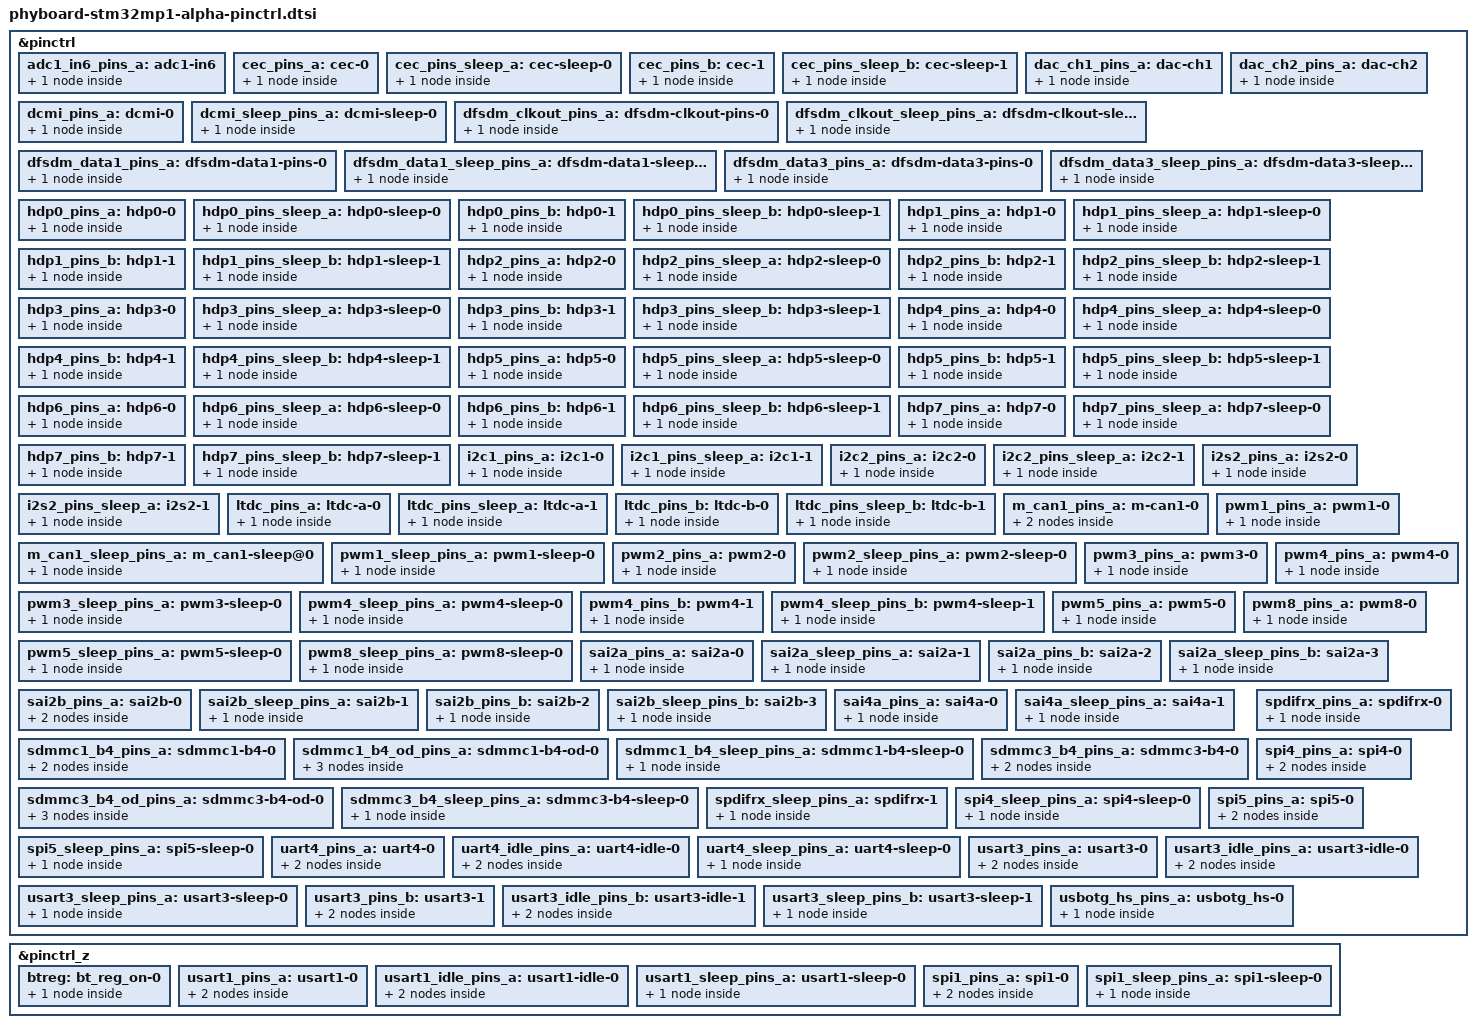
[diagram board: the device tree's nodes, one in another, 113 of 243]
// SPDX-License-Identifier: (GPL-2.0+ OR BSD-3-Clause)
/*
 * Copyright (C) PHYTEC GmbH 2019-2020 - All Rights Reserved
 * Author: Dom VOVARD <dom.vovard@linrt.com>.
 */

#include <dt-bindings/pinctrl/stm32-pinfunc.h>

&pinctrl {
			adc1_in6_pins_a: adc1-in6 {
				pins {
					pinmux = <STM32_PINMUX('F', 12, ANALOG)>;
				};
			};

			cec_pins_a: cec-0 {
				pins {
					pinmux = <STM32_PINMUX('A', 15, AF4)>;
					bias-disable;
					drive-open-drain;
					slew-rate = <0>;
				};
			};

			cec_pins_sleep_a: cec-sleep-0 {
				pins {
					pinmux = <STM32_PINMUX('A', 15, ANALOG)>; /* HDMI_CEC */
				};
			};

			cec_pins_b: cec-1 {
				pins {
					pinmux = <STM32_PINMUX('B', 6, AF5)>;
					bias-disable;
					drive-open-drain;
					slew-rate = <0>;
				};
			};

			cec_pins_sleep_b: cec-sleep-1 {
				pins {
					pinmux = <STM32_PINMUX('B', 6, ANALOG)>; /* HDMI_CEC */
				};
			};

			dac_ch1_pins_a: dac-ch1 {
				pins {
					pinmux = <STM32_PINMUX('A', 4, ANALOG)>;
				};
			};

			dac_ch2_pins_a: dac-ch2 {
				pins {
					pinmux = <STM32_PINMUX('A', 5, ANALOG)>;
				};
			};

			dcmi_pins_a: dcmi-0 {
				pins {
					pinmux = <STM32_PINMUX('H', 8,  AF13)>,/* DCMI_HSYNC */
						 <STM32_PINMUX('B', 7,  AF13)>,/* DCMI_VSYNC */
						 <STM32_PINMUX('A', 6,  AF13)>,/* DCMI_PIXCLK */
						 <STM32_PINMUX('H', 9,  AF13)>,/* DCMI_D0 */
						 <STM32_PINMUX('H', 10, AF13)>,/* DCMI_D1 */
						 <STM32_PINMUX('H', 11, AF13)>,/* DCMI_D2 */
						 <STM32_PINMUX('H', 12, AF13)>,/* DCMI_D3 */
						 <STM32_PINMUX('H', 14, AF13)>,/* DCMI_D4 */
						 <STM32_PINMUX('I', 4,  AF13)>,/* DCMI_D5 */
						 <STM32_PINMUX('B', 8,  AF13)>,/* DCMI_D6 */
						 <STM32_PINMUX('E', 6,  AF13)>,/* DCMI_D7 */
						 <STM32_PINMUX('I', 1,  AF13)>,/* DCMI_D8 */
						 <STM32_PINMUX('H', 7,  AF13)>,/* DCMI_D9 */
						 <STM32_PINMUX('I', 3,  AF13)>,/* DCMI_D10 */
						 <STM32_PINMUX('H', 15, AF13)>;/* DCMI_D11 */
					bias-disable;
				};
			};

			dcmi_sleep_pins_a: dcmi-sleep-0 {
				pins {
					pinmux = <STM32_PINMUX('H', 8,  ANALOG)>,/* DCMI_HSYNC */
						 <STM32_PINMUX('B', 7,  ANALOG)>,/* DCMI_VSYNC */
						 <STM32_PINMUX('A', 6,  ANALOG)>,/* DCMI_PIXCLK */
						 <STM32_PINMUX('H', 9,  ANALOG)>,/* DCMI_D0 */
						 <STM32_PINMUX('H', 10, ANALOG)>,/* DCMI_D1 */
						 <STM32_PINMUX('H', 11, ANALOG)>,/* DCMI_D2 */
						 <STM32_PINMUX('H', 12, ANALOG)>,/* DCMI_D3 */
						 <STM32_PINMUX('H', 14, ANALOG)>,/* DCMI_D4 */
						 <STM32_PINMUX('I', 4,  ANALOG)>,/* DCMI_D5 */
						 <STM32_PINMUX('B', 8,  ANALOG)>,/* DCMI_D6 */
						 <STM32_PINMUX('E', 6,  ANALOG)>,/* DCMI_D7 */
						 <STM32_PINMUX('I', 1,  ANALOG)>,/* DCMI_D8 */
						 <STM32_PINMUX('H', 7,  ANALOG)>,/* DCMI_D9 */
						 <STM32_PINMUX('I', 3,  ANALOG)>,/* DCMI_D10 */
						 <STM32_PINMUX('H', 15, ANALOG)>;/* DCMI_D11 */
				};
			};

			dfsdm_clkout_pins_a: dfsdm-clkout-pins-0 {
				pins {
					pinmux = <STM32_PINMUX('B', 13, AF3)>; /* DFSDM_CKOUT */
					bias-disable;
					drive-push-pull;
					slew-rate = <1>;
				};
			};

			dfsdm_clkout_sleep_pins_a: dfsdm-clkout-sleep-pins-0 {
				pins {
					pinmux = <STM32_PINMUX('B', 13, ANALOG)>; /* DFSDM_CKOUT */
				};
			};

			dfsdm_data1_pins_a: dfsdm-data1-pins-0 {
				pins {
					pinmux = <STM32_PINMUX('C', 3, AF3)>; /* DFSDM_DATA1 */
				};
			};

			dfsdm_data1_sleep_pins_a: dfsdm-data1-sleep-pins-0 {
				pins {
					pinmux = <STM32_PINMUX('C', 3, ANALOG)>; /* DFSDM_DATA1 */
				};
			};

			dfsdm_data3_pins_a: dfsdm-data3-pins-0 {
				pins {
					pinmux = <STM32_PINMUX('F', 13, AF6)>; /* DFSDM_DATA3 */
				};
			};

			dfsdm_data3_sleep_pins_a: dfsdm-data3-sleep-pins-0 {
				pins {
					pinmux = <STM32_PINMUX('F', 13, ANALOG)>; /* DFSDM_DATA3 */
				};
			};

			hdp0_pins_a: hdp0-0 {
				pins {
					pinmux = <STM32_PINMUX('I', 12, AF2)>; /* HDP0 */
					bias-disable;
					drive-push-pull;
					slew-rate = <2>;
				};
			};

			hdp0_pins_sleep_a: hdp0-sleep-0 {
				pins {
					pinmux = <STM32_PINMUX('I', 12, ANALOG)>; /* HDP0 */
				};
			};

			hdp0_pins_b: hdp0-1 {
				pins {
					pinmux = <STM32_PINMUX('I', 10, AF0)>; /* HDP0 */
					bias-disable;
					drive-push-pull;
					slew-rate = <2>;
				};
			};

			hdp0_pins_sleep_b: hdp0-sleep-1 {
				pins {
					pinmux = <STM32_PINMUX('I', 10, ANALOG)>; /* HDP0 */
				};
			};

			hdp1_pins_a: hdp1-0 {
				pins {
					pinmux = <STM32_PINMUX('I', 13, AF2)>; /* HDP1 */
					bias-disable;
					drive-push-pull;
					slew-rate = <2>;
				};
			};

			hdp1_pins_sleep_a: hdp1-sleep-0 {
				pins {
					pinmux = <STM32_PINMUX('I', 13, ANALOG)>; /* HDP1 */
				};
			};

			hdp1_pins_b: hdp1-1 {
				pins {
					pinmux = <STM32_PINMUX('I', 9, AF0)>; /* HDP1 */
					bias-disable;
					drive-push-pull;
					slew-rate = <2>;
				};
			};

			hdp1_pins_sleep_b: hdp1-sleep-1 {
				pins {
					pinmux = <STM32_PINMUX('I', 9, ANALOG)>; /* HDP1 */
				};
			};

			hdp2_pins_a: hdp2-0 {
				pins {
					pinmux = <STM32_PINMUX('J', 5, AF2)>; /* HDP2 */
					bias-disable;
					drive-push-pull;
					slew-rate = <2>;
				};
			};

			hdp2_pins_sleep_a: hdp2-sleep-0 {
				pins {
					pinmux = <STM32_PINMUX('J', 5, ANALOG)>; /* HDP2 */
				};
			};

			hdp2_pins_b: hdp2-1 {
				pins {
					pinmux = <STM32_PINMUX('E', 13, AF0)>; /* HDP2 */
					bias-disable;
					drive-push-pull;
					slew-rate = <2>;
				};
			};

			hdp2_pins_sleep_b: hdp2-sleep-1 {
				pins {
					pinmux = <STM32_PINMUX('E', 13, ANALOG)>; /* HDP2 */
				};
			};

			hdp3_pins_a: hdp3-0 {
				pins {
					pinmux = <STM32_PINMUX('J', 6, AF2)>; /* HDP3 */
					bias-disable;
					drive-push-pull;
					slew-rate = <2>;
				};
			};

			hdp3_pins_sleep_a: hdp3-sleep-0 {
				pins {
					pinmux = <STM32_PINMUX('J', 6, ANALOG)>; /* HDP3 */
				};
			};

			hdp3_pins_b: hdp3-1 {
				pins {
					pinmux = <STM32_PINMUX('E', 15, AF0)>; /* HDP3 */
					bias-disable;
					drive-push-pull;
					slew-rate = <2>;
				};
			};

			hdp3_pins_sleep_b: hdp3-sleep-1 {
				pins {
					pinmux = <STM32_PINMUX('E', 15, ANALOG)>; /* HDP3 */
				};
			};

			hdp4_pins_a: hdp4-0 {
				pins {
					pinmux = <STM32_PINMUX('K', 1, AF2)>; /* HDP4 */
					bias-disable;
					drive-push-pull;
					slew-rate = <2>;
				};
			};

			hdp4_pins_sleep_a: hdp4-sleep-0 {
				pins {
					pinmux = <STM32_PINMUX('K', 1, ANALOG)>; /* HDP4 */
				};
			};

			hdp4_pins_b: hdp4-1 {
				pins {
					pinmux = <STM32_PINMUX('C', 7, AF0)>; /* HDP4 */
					bias-disable;
					drive-push-pull;
					slew-rate = <2>;
				};
			};

			hdp4_pins_sleep_b: hdp4-sleep-1 {
				pins {
					pinmux = <STM32_PINMUX('C', 7, ANALOG)>; /* HDP4 */
				};
			};

			hdp5_pins_a: hdp5-0 {
				pins {
					pinmux = <STM32_PINMUX('K', 2, AF2)>; /* HDP5 */
					bias-disable;
					drive-push-pull;
					slew-rate = <2>;
				};
			};

			hdp5_pins_sleep_a: hdp5-sleep-0 {
				pins {
					pinmux = <STM32_PINMUX('K', 2, ANALOG)>; /* HDP5 */
				};
			};

			hdp5_pins_b: hdp5-1 {
				pins {
					pinmux = <STM32_PINMUX('D', 3, AF0)>; /* HDP5 */
					bias-disable;
					drive-push-pull;
					slew-rate = <2>;
				};
			};

			hdp5_pins_sleep_b: hdp5-sleep-1 {
				pins {
					pinmux = <STM32_PINMUX('D', 3, ANALOG)>; /* HDP5 */
				};
			};

			hdp6_pins_a: hdp6-0 {
				pins {
					pinmux = <STM32_PINMUX('K', 5, AF2)>; /* HDP6 */
					bias-disable;
					drive-push-pull;
					slew-rate = <2>;
				};
			};

			hdp6_pins_sleep_a: hdp6-sleep-0 {
				pins {
					pinmux = <STM32_PINMUX('K', 5, ANALOG)>; /* HDP6 */
				};
			};

			hdp6_pins_b: hdp6-1 {
				pins {
					pinmux = <STM32_PINMUX('B', 8, AF0)>; /* HDP6 */
					bias-disable;
					drive-push-pull;
					slew-rate = <2>;
				};
			};

			hdp6_pins_sleep_b: hdp6-sleep-1 {
				pins {
					pinmux = <STM32_PINMUX('B', 8, ANALOG)>; /* HDP6 */
				};
			};

			hdp7_pins_a: hdp7-0 {
				pins {
					pinmux = <STM32_PINMUX('K', 6, AF2)>; /* HDP7 */
					bias-disable;
					drive-push-pull;
					slew-rate = <2>;
				};
			};

			hdp7_pins_sleep_a: hdp7-sleep-0 {
				pins {
					pinmux = <STM32_PINMUX('K', 6, ANALOG)>; /* HDP7 */
				};
			};

			hdp7_pins_b: hdp7-1 {
				pins {
					pinmux = <STM32_PINMUX('B', 9, AF0)>; /* HDP7 */
					bias-disable;
					drive-push-pull;
					slew-rate = <2>;
				};
			};

			hdp7_pins_sleep_b: hdp7-sleep-1 {
				pins {
					pinmux = <STM32_PINMUX('B', 9, ANALOG)>; /* HDP7 */
				};
			};

			i2c1_pins_a: i2c1-0 {
				pins {
					pinmux = <STM32_PINMUX('F', 14, AF5)>, /* I2C1_SCL */
						 <STM32_PINMUX('F', 15, AF5)>; /* I2C1_SDA */
					bias-disable;
					drive-open-drain;
					slew-rate = <0>;
				};
			};

			i2c1_pins_sleep_a: i2c1-1 {
				pins {
					pinmux = <STM32_PINMUX('D', 12, ANALOG)>, /* I2C1_SCL */
						 <STM32_PINMUX('F', 15, ANALOG)>; /* I2C1_SDA */
				};
			};

			i2c2_pins_a: i2c2-0 {
				pins {
					pinmux = <STM32_PINMUX('H', 4, AF4)>, /* I2C2_SCL */
						 <STM32_PINMUX('H', 5, AF4)>; /* I2C2_SDA */
					bias-disable;
					drive-open-drain;
					slew-rate = <0>;
				};
			};

			i2c2_pins_sleep_a: i2c2-1 {
				pins {
					pinmux = <STM32_PINMUX('H', 4, ANALOG)>, /* I2C2_SCL */
						 <STM32_PINMUX('H', 5, ANALOG)>; /* I2C2_SDA */
				};
			};

			i2s2_pins_a: i2s2-0 {
				pins {
					pinmux = <STM32_PINMUX('I', 3, AF5)>, /* I2S2_SDO */
						 <STM32_PINMUX('B', 9, AF5)>, /* I2S2_WS */
						 <STM32_PINMUX('A', 9, AF5)>; /* I2S2_CK */
					slew-rate = <1>;
					drive-push-pull;
					bias-disable;
				};
			};

			i2s2_pins_sleep_a: i2s2-1 {
				pins {
					pinmux = <STM32_PINMUX('I', 3, ANALOG)>, /* I2S2_SDO */
						 <STM32_PINMUX('B', 9, ANALOG)>, /* I2S2_WS */
						 <STM32_PINMUX('A', 9, ANALOG)>; /* I2S2_CK */
				};
			};

			ltdc_pins_a: ltdc-a-0 {
				pins {
					pinmux = <STM32_PINMUX('G',  7, AF14)>, /* LCD_CLK */
						 <STM32_PINMUX('I', 10, AF14)>, /* LCD_HSYNC */
						 <STM32_PINMUX('I',  9, AF14)>, /* LCD_VSYNC */
						 <STM32_PINMUX('E', 13, AF14)>, /* LCD_DE */
						 <STM32_PINMUX('C', 10, AF14)>, /* LCD_R2 */
						 <STM32_PINMUX('B',   0, AF9)>, /* LCD_R3 */
						 <STM32_PINMUX('H', 10, AF14)>, /* LCD_R4 */
						 <STM32_PINMUX('H', 11, AF14)>, /* LCD_R5 */
						 <STM32_PINMUX('H', 12, AF14)>, /* LCD_R6 */
						 <STM32_PINMUX('E', 15, AF14)>, /* LCD_R7 */
						 <STM32_PINMUX('H', 13, AF14)>, /* LCD_G2 */
						 <STM32_PINMUX('E', 11, AF14)>, /* LCD_G3 */
						 <STM32_PINMUX('H', 15, AF14)>, /* LCD_G4 */
						 <STM32_PINMUX('H',  4,  AF9)>, /* LCD_G5 */
						 <STM32_PINMUX('I', 11,  AF9)>, /* LCD_G6 */
						 <STM32_PINMUX('I',  2, AF14)>, /* LCD_G7 */
						 <STM32_PINMUX('G', 10, AF14)>, /* LCD_B2 */
						 <STM32_PINMUX('G', 11, AF14)>, /* LCD_B3 */
						 <STM32_PINMUX('E', 12, AF14)>, /* LCD_B4 */
						 <STM32_PINMUX('I',  5, AF14)>, /* LCD_B5 */
						 <STM32_PINMUX('B',  8, AF14)>, /* LCD_B6 */
						 <STM32_PINMUX('D',  8, AF14)>; /* LCD_B7 */
					bias-disable;
					drive-push-pull;
					slew-rate = <1>;
				};
			};

			ltdc_pins_sleep_a: ltdc-a-1 {
				pins {
                                        pinmux = <STM32_PINMUX('G',  7, ANALOG)>, /* LCD_CLK */
                                                 <STM32_PINMUX('I', 10, ANALOG)>, /* LCD_HSYNC */
                                                 <STM32_PINMUX('I',  9, ANALOG)>, /* LCD_VSYNC */
                                                 <STM32_PINMUX('E', 13, ANALOG)>, /* LCD_DE */
                                                 <STM32_PINMUX('C', 10, ANALOG)>, /* LCD_R2 */
                                                 <STM32_PINMUX('B',  0, ANALOG)>, /* LCD_R3 */
                                                 <STM32_PINMUX('H', 10, ANALOG)>, /* LCD_R4 */
                                                 <STM32_PINMUX('H', 11, ANALOG)>, /* LCD_R5 */
                                                 <STM32_PINMUX('H', 12, ANALOG)>, /* LCD_R6 */
                                                 <STM32_PINMUX('E', 15, ANALOG)>, /* LCD_R7 */
                                                 <STM32_PINMUX('H', 13, ANALOG)>, /* LCD_G2 */
                                                 <STM32_PINMUX('E', 11, ANALOG)>, /* LCD_G3 */
                                                 <STM32_PINMUX('H', 15, ANALOG)>, /* LCD_G4 */
                                                 <STM32_PINMUX('H',  4, ANALOG)>, /* LCD_G5 */
                                                 <STM32_PINMUX('I', 11, ANALOG)>, /* LCD_G6 */
                                                 <STM32_PINMUX('I',  2, ANALOG)>, /* LCD_G7 */
                                                 <STM32_PINMUX('G', 10, ANALOG)>, /* LCD_B2 */
                                                 <STM32_PINMUX('G', 11, ANALOG)>, /* LCD_B3 */
                                                 <STM32_PINMUX('E', 12, ANALOG)>, /* LCD_B4 */
                                                 <STM32_PINMUX('I',  5, ANALOG)>, /* LCD_B5 */
                                                 <STM32_PINMUX('B',  8, ANALOG)>, /* LCD_B6 */
                                                 <STM32_PINMUX('D',  8, ANALOG)>; /* LCD_B7 */
                                };
			};

			ltdc_pins_b: ltdc-b-0 {
				pins {
					pinmux = <STM32_PINMUX('I', 14, AF14)>, /* LCD_CLK */
						 <STM32_PINMUX('I', 12, AF14)>, /* LCD_HSYNC */
						 <STM32_PINMUX('I', 13, AF14)>, /* LCD_VSYNC */
						 <STM32_PINMUX('K',  7, AF14)>, /* LCD_DE */
						 <STM32_PINMUX('I', 15, AF14)>, /* LCD_R0 */
						 <STM32_PINMUX('J',  0, AF14)>, /* LCD_R1 */
						 <STM32_PINMUX('J',  1, AF14)>, /* LCD_R2 */
						 <STM32_PINMUX('J',  2, AF14)>, /* LCD_R3 */
						 <STM32_PINMUX('J',  3, AF14)>, /* LCD_R4 */
						 <STM32_PINMUX('J',  4, AF14)>, /* LCD_R5 */
						 <STM32_PINMUX('J',  5, AF14)>, /* LCD_R6 */
						 <STM32_PINMUX('J',  6, AF14)>, /* LCD_R7 */
						 <STM32_PINMUX('J',  7, AF14)>, /* LCD_G0 */
						 <STM32_PINMUX('J',  8, AF14)>, /* LCD_G1 */
						 <STM32_PINMUX('J',  9, AF14)>, /* LCD_G2 */
						 <STM32_PINMUX('J', 10, AF14)>, /* LCD_G3 */
						 <STM32_PINMUX('J', 11, AF14)>, /* LCD_G4 */
						 <STM32_PINMUX('K',  0, AF14)>, /* LCD_G5 */
						 <STM32_PINMUX('K',  1, AF14)>, /* LCD_G6 */
						 <STM32_PINMUX('K',  2, AF14)>, /* LCD_G7 */
						 <STM32_PINMUX('J', 12, AF14)>, /* LCD_B0 */
						 <STM32_PINMUX('J', 13, AF14)>, /* LCD_B1 */
						 <STM32_PINMUX('J', 14, AF14)>, /* LCD_B2 */
						 <STM32_PINMUX('J', 15, AF14)>, /* LCD_B3 */
						 <STM32_PINMUX('K',  3, AF14)>, /* LCD_B4 */
						 <STM32_PINMUX('K',  4, AF14)>, /* LCD_B5 */
						 <STM32_PINMUX('K',  5, AF14)>, /* LCD_B6 */
						 <STM32_PINMUX('K',  6, AF14)>; /* LCD_B7 */
					bias-disable;
					drive-push-pull;
					slew-rate = <1>;
				};
			};

			ltdc_pins_sleep_b: ltdc-b-1 {
				pins {
					pinmux = <STM32_PINMUX('I', 14, ANALOG)>, /* LCD_CLK */
						 <STM32_PINMUX('I', 12, ANALOG)>, /* LCD_HSYNC */
						 <STM32_PINMUX('I', 13, ANALOG)>, /* LCD_VSYNC */
						 <STM32_PINMUX('K',  7, ANALOG)>, /* LCD_DE */
						 <STM32_PINMUX('I', 15, ANALOG)>, /* LCD_R0 */
						 <STM32_PINMUX('J',  0, ANALOG)>, /* LCD_R1 */
						 <STM32_PINMUX('J',  1, ANALOG)>, /* LCD_R2 */
						 <STM32_PINMUX('J',  2, ANALOG)>, /* LCD_R3 */
						 <STM32_PINMUX('J',  3, ANALOG)>, /* LCD_R4 */
						 <STM32_PINMUX('J',  4, ANALOG)>, /* LCD_R5 */
						 <STM32_PINMUX('J',  5, ANALOG)>, /* LCD_R6 */
						 <STM32_PINMUX('J',  6, ANALOG)>, /* LCD_R7 */
						 <STM32_PINMUX('J',  7, ANALOG)>, /* LCD_G0 */
						 <STM32_PINMUX('J',  8, ANALOG)>, /* LCD_G1 */
						 <STM32_PINMUX('J',  9, ANALOG)>, /* LCD_G2 */
						 <STM32_PINMUX('J', 10, ANALOG)>, /* LCD_G3 */
						 <STM32_PINMUX('J', 11, ANALOG)>, /* LCD_G4 */
						 <STM32_PINMUX('K',  0, ANALOG)>, /* LCD_G5 */
						 <STM32_PINMUX('K',  1, ANALOG)>, /* LCD_G6 */
						 <STM32_PINMUX('K',  2, ANALOG)>, /* LCD_G7 */
						 <STM32_PINMUX('J', 12, ANALOG)>, /* LCD_B0 */
						 <STM32_PINMUX('J', 13, ANALOG)>, /* LCD_B1 */
						 <STM32_PINMUX('J', 14, ANALOG)>, /* LCD_B2 */
						 <STM32_PINMUX('J', 15, ANALOG)>, /* LCD_B3 */
						 <STM32_PINMUX('K',  3, ANALOG)>, /* LCD_B4 */
						 <STM32_PINMUX('K',  4, ANALOG)>, /* LCD_B5 */
						 <STM32_PINMUX('K',  5, ANALOG)>, /* LCD_B6 */
						 <STM32_PINMUX('K',  6, ANALOG)>; /* LCD_B7 */
				};
			};

			m_can1_pins_a: m-can1-0 {
				pins1 {
					pinmux = <STM32_PINMUX('A', 12, AF9)>; /* CAN1_TX */
					slew-rate = <0>;
					drive-push-pull;
					bias-disable;
				};
				pins2 {
					pinmux = <STM32_PINMUX('A', 11, AF9)>; /* CAN1_RX */
                                                bias-disable;
				};
			};

			m_can1_sleep_pins_a: m_can1-sleep@0 {
				pins {
					pinmux = <STM32_PINMUX('A', 12, ANALOG)>, /* CAN1_TX */
						 <STM32_PINMUX('A', 11, ANALOG)>; /* CAN1_RX */
				};
			};

			pwm1_pins_a: pwm1-0 {
				pins {
					pinmux = <STM32_PINMUX('E', 9, AF1)>, /* TIM1_CH1 */
						 <STM32_PINMUX('E', 11, AF1)>, /* TIM1_CH2 */
						 <STM32_PINMUX('E', 14, AF1)>; /* TIM1_CH4 */
					bias-pull-down;
					drive-push-pull;
					slew-rate = <0>;
				};
			};

			pwm1_sleep_pins_a: pwm1-sleep-0 {
				pins {
					pinmux = <STM32_PINMUX('E', 9, ANALOG)>, /* TIM1_CH1 */
						 <STM32_PINMUX('E', 11, ANALOG)>, /* TIM1_CH2 */
						 <STM32_PINMUX('E', 14, ANALOG)>; /* TIM1_CH4 */
				};
			};

			pwm2_pins_a: pwm2-0 {
				pins {
					pinmux = <STM32_PINMUX('A', 3, AF1)>; /* TIM2_CH4 */
					bias-pull-down;
					drive-push-pull;
					slew-rate = <0>;
				};
			};

			pwm2_sleep_pins_a: pwm2-sleep-0 {
				pins {
					pinmux = <STM32_PINMUX('A', 3, ANALOG)>; /* TIM2_CH4 */
				};
			};

			pwm3_pins_a: pwm3-0 {
				pins {
					pinmux = <STM32_PINMUX('C', 7, AF2)>; /* TIM3_CH2 */
					bias-pull-down;
					drive-push-pull;
					slew-rate = <0>;
				};
			};

			pwm3_sleep_pins_a: pwm3-sleep-0 {
				pins {
					pinmux = <STM32_PINMUX('C', 7, ANALOG)>; /* TIM3_CH2 */
				};
			};

			pwm4_pins_a: pwm4-0 {
				pins {
					pinmux = <STM32_PINMUX('D', 14, AF2)>, /* TIM4_CH3 */
						 <STM32_PINMUX('D', 15, AF2)>; /* TIM4_CH4 */
					bias-pull-down;
					drive-push-pull;
					slew-rate = <0>;
				};
			};

			pwm4_sleep_pins_a: pwm4-sleep-0 {
				pins {
					pinmux = <STM32_PINMUX('D', 14, ANALOG)>, /* TIM4_CH3 */
						 <STM32_PINMUX('D', 15, ANALOG)>; /* TIM4_CH4 */
				};
			};

			pwm4_pins_b: pwm4-1 {
				pins {
					pinmux = <STM32_PINMUX('D', 13, AF2)>; /* TIM4_CH2 */
					bias-pull-down;
					drive-push-pull;
					slew-rate = <0>;
				};
			};

			pwm4_sleep_pins_b: pwm4-sleep-1 {
				pins {
					pinmux = <STM32_PINMUX('D', 13, ANALOG)>; /* TIM4_CH2 */
				};
			};

			pwm5_pins_a: pwm5-0 {
				pins {
					pinmux = <STM32_PINMUX('I', 0, AF2)>; /* TIM5_CH4 */
					bias-pull-down;
					drive-push-pull;
					slew-rate = <0>;
				};
			};

			pwm5_sleep_pins_a: pwm5-sleep-0 {
				pins {
					pinmux = <STM32_PINMUX('I', 0, ANALOG)>; /* TIM5_CH4 */
				};
			};

			pwm8_pins_a: pwm8-0 {
				pins {
					pinmux = <STM32_PINMUX('I', 2, AF3)>; /* TIM8_CH4 */
					bias-pull-down;
					drive-push-pull;
					slew-rate = <0>;
				};
			};

			pwm8_sleep_pins_a: pwm8-sleep-0 {
				pins {
					pinmux = <STM32_PINMUX('I', 2, ANALOG)>; /* TIM8_CH4 */
				};
			};

			sai2a_pins_a: sai2a-0 {
				pins {
					pinmux = <STM32_PINMUX('I', 5, AF10)>, /* SAI2_SCK_A */
						 <STM32_PINMUX('I', 6, AF10)>, /* SAI2_SD_A */
						 <STM32_PINMUX('I', 7, AF10)>, /* SAI2_FS_A */
						 <STM32_PINMUX('E', 0, AF10)>; /* SAI2_MCLK_A */
					slew-rate = <0>;
					drive-push-pull;
					bias-disable;
				};
			};

			sai2a_sleep_pins_a: sai2a-1 {
				pins {
					pinmux = <STM32_PINMUX('I', 5, ANALOG)>, /* SAI2_SCK_A */
						 <STM32_PINMUX('I', 6, ANALOG)>, /* SAI2_SD_A */
						 <STM32_PINMUX('I', 7, ANALOG)>, /* SAI2_FS_A */
						 <STM32_PINMUX('E', 0, ANALOG)>; /* SAI2_MCLK_A */
				};
			};

                        sai2a_pins_b: sai2a-2 {
                                pins {
                                        pinmux = <STM32_PINMUX('I', 6, AF10)>; /* SAI2_SD_A */
                                        bias-disable;
                                };
                        };

                        sai2a_sleep_pins_b: sai2a-3 {
                                pins {
                                        pinmux = <STM32_PINMUX('I', 6, ANALOG)>; /* SAI2_SD_A */
                                };
                        };

			sai2b_pins_a: sai2b-0 {
				pins1 {
					pinmux = <STM32_PINMUX('H', 2, AF10)>, /* SAI2_SCK_B */
						 <STM32_PINMUX('C', 0, AF8)>, /* SAI2_FS_B */
						 <STM32_PINMUX('H', 3, AF10)>; /* SAI2_MCLK_B */
					slew-rate = <0>;
					drive-push-pull;
					bias-disable;
				};
				pins2 {
					pinmux = <STM32_PINMUX('F', 11, AF10)>; /* SAI2_SD_B */
					bias-disable;
				};
			};

			sai2b_sleep_pins_a: sai2b-1 {
				pins {
					pinmux = <STM32_PINMUX('F', 11, ANALOG)>, /* SAI2_SD_B */
						 <STM32_PINMUX('H', 2, ANALOG)>, /* SAI2_SCK_B */
						 <STM32_PINMUX('C', 0, ANALOG)>, /* SAI2_FS_B */
						 <STM32_PINMUX('H', 3, ANALOG)>; /* SAI2_MCLK_B */
				};
			};

			sai2b_pins_b: sai2b-2 {
				pins {
					pinmux = <STM32_PINMUX('F', 11, AF10)>; /* SAI2_SD_B */
					bias-disable;
				};
			};

			sai2b_sleep_pins_b: sai2b-3 {
				pins {
					pinmux = <STM32_PINMUX('F', 11, ANALOG)>; /* SAI2_SD_B */
				};
			};

			sai4a_pins_a: sai4a-0 {
				pins {
					pinmux = <STM32_PINMUX('B', 5, AF10)>; /* SAI4_SD_A */
					slew-rate = <0>;
					drive-push-pull;
					bias-disable;
				};
			};

			sai4a_sleep_pins_a: sai4a-1 {
				pins {
					pinmux = <STM32_PINMUX('B', 5, ANALOG)>; /* SAI4_SD_A */
				};
			};

			sdmmc1_b4_pins_a: sdmmc1-b4-0 {
				pins1 {
					pinmux = <STM32_PINMUX('C', 8, AF12)>, /* SDMMC1_D0 */
						 <STM32_PINMUX('C', 9, AF12)>, /* SDMMC1_D1 */
						 <STM32_PINMUX('E', 6, AF8)>, /* SDMMC1_D2 */
						 <STM32_PINMUX('C', 11, AF12)>, /* SDMMC1_D3 */
						 <STM32_PINMUX('D', 2, AF12)>; /* SDMMC1_CMD */
					slew-rate = <1>;
					drive-push-pull;
					bias-disable;
				};
				pins2 {
					pinmux = <STM32_PINMUX('C', 12, AF12)>; /* SDMMC1_CK */
					slew-rate = <2>;
					drive-push-pull;
					bias-disable;
				};
			};

			sdmmc1_b4_od_pins_a: sdmmc1-b4-od-0 {
				pins1 {
					pinmux = <STM32_PINMUX('C', 8, AF12)>, /* SDMMC1_D0 */
						 <STM32_PINMUX('C', 9, AF12)>, /* SDMMC1_D1 */
						 <STM32_PINMUX('E', 6, AF8)>, /* SDMMC1_D2 */
						 <STM32_PINMUX('C', 11, AF12)>; /* SDMMC1_D3 */
					slew-rate = <1>;
					drive-push-pull;
					bias-disable;
				};
				pins2 {
					pinmux = <STM32_PINMUX('C', 12, AF12)>; /* SDMMC1_CK */
					slew-rate = <2>;
					drive-push-pull;
					bias-disable;
				};
				pins3 {
					pinmux = <STM32_PINMUX('D', 2, AF12)>; /* SDMMC1_CMD */
					slew-rate = <1>;
					drive-open-drain;
					bias-disable;
				};
			};

			sdmmc1_b4_sleep_pins_a: sdmmc1-b4-sleep-0 {
				pins {
					pinmux = <STM32_PINMUX('C', 8, ANALOG)>, /* SDMMC1_D0 */
						 <STM32_PINMUX('C', 9, ANALOG)>, /* SDMMC1_D1 */
						 <STM32_PINMUX('E', 6, ANALOG)>, /* SDMMC1_D2 */
						 <STM32_PINMUX('C', 11, ANALOG)>, /* SDMMC1_D3 */
						 <STM32_PINMUX('C', 12, ANALOG)>, /* SDMMC1_CK */
						 <STM32_PINMUX('D', 2, ANALOG)>; /* SDMMC1_CMD */
				};
			};

			sdmmc3_b4_pins_a: sdmmc3-b4-0 {
				pins1 {
					pinmux = <STM32_PINMUX('F', 0, AF9)>, /* SDMMC3_D0 */
						 <STM32_PINMUX('F', 4, AF9)>, /* SDMMC3_D1 */
						 <STM32_PINMUX('F', 5, AF9)>, /* SDMMC3_D2 */
						 <STM32_PINMUX('D', 7, AF10)>, /* SDMMC3_D3 */
						 <STM32_PINMUX('F', 1, AF9)>; /* SDMMC3_CMD */
					slew-rate = <1>;
					drive-push-pull;
					bias-pull-up;
				};
				pins2 {
					pinmux = <STM32_PINMUX('G', 15, AF10)>; /* SDMMC3_CK */
					slew-rate = <2>;
					drive-push-pull;
					bias-pull-up;
				};
			};

			sdmmc3_b4_od_pins_a: sdmmc3-b4-od-0 {
				pins1 {
					pinmux = <STM32_PINMUX('F', 0, AF9)>, /* SDMMC3_D0 */
						 <STM32_PINMUX('F', 4, AF9)>, /* SDMMC3_D1 */
						 <STM32_PINMUX('F', 5, AF9)>, /* SDMMC3_D2 */
						 <STM32_PINMUX('D', 7, AF10)>; /* SDMMC3_D3 */
					slew-rate = <1>;
					drive-push-pull;
					bias-pull-up;
				};
				pins2 {
					pinmux = <STM32_PINMUX('G', 15, AF10)>; /* SDMMC3_CK */
					slew-rate = <2>;
					drive-push-pull;
					bias-pull-up;
				};
				pins3 {
					pinmux = <STM32_PINMUX('F', 1, AF9)>; /* SDMMC2_CMD */
					slew-rate = <1>;
					drive-open-drain;
					bias-pull-up;
				};
			};

			sdmmc3_b4_sleep_pins_a: sdmmc3-b4-sleep-0 {
				pins {
					pinmux = <STM32_PINMUX('F', 0, ANALOG)>, /* SDMMC3_D0 */
						 <STM32_PINMUX('F', 4, ANALOG)>, /* SDMMC3_D1 */
						 <STM32_PINMUX('F', 5, ANALOG)>, /* SDMMC3_D2 */
						 <STM32_PINMUX('D', 7, ANALOG)>, /* SDMMC3_D3 */
						 <STM32_PINMUX('G', 15, ANALOG)>, /* SDMMC3_CK */
						 <STM32_PINMUX('F', 1, ANALOG)>; /* SDMMC3_CMD */
				};
			};

			spdifrx_pins_a: spdifrx-0 {
				pins {
					pinmux = <STM32_PINMUX('G', 12, AF8)>; /* SPDIF_IN1 */
					bias-disable;
				};
			};

			spdifrx_sleep_pins_a: spdifrx-1 {
				pins {
					pinmux = <STM32_PINMUX('G', 12, ANALOG)>; /* SPDIF_IN1 */
				};
			};

			spi4_pins_a: spi4-0 {
				pins1 {
					pinmux = <STM32_PINMUX('E', 12, AF5)>, /* SPI4_SCK */
						 <STM32_PINMUX('E', 14, AF5)>; /* SPI4_MOSI */
					bias-disable;
					drive-push-pull;
					slew-rate = <1>;
				};

				pins2 {
					pinmux = <STM32_PINMUX('E', 13, AF5)>; /* SPI4_MISO */
					bias-disable;
				};
			};

			spi4_sleep_pins_a: spi4-sleep-0 {
				pins {
					pinmux = <STM32_PINMUX('E', 12, ANALOG)>, /* SPI4_SCK */
						 <STM32_PINMUX('E', 13, ANALOG)>, /* SPI4_MISO */
						 <STM32_PINMUX('E', 14, ANALOG)>; /* SPI4_MOSI */
				};
			};

			spi5_pins_a: spi5-0 {
				pins1 {
					pinmux = <STM32_PINMUX('F', 7, AF5)>, /* SPI5_SCK */
						 <STM32_PINMUX('F', 9, AF5)>; /* SPI5_MOSI */
					bias-disable;
					drive-push-pull;
					slew-rate = <1>;
				};

				pins2 {
					pinmux = <STM32_PINMUX('F', 8, AF5)>; /* SPI5_MISO */
					bias-disable;
				};
			};

			spi5_sleep_pins_a: spi5-sleep-0 {
				pins {
					pinmux = <STM32_PINMUX('F', 7, ANALOG)>, /* SPI5_SCK */
						 <STM32_PINMUX('F', 8, ANALOG)>, /* SPI5_MISO */
						 <STM32_PINMUX('F', 9, ANALOG)>; /* SPI5_MOSI */
				};
			};

			uart4_pins_a: uart4-0 {
				pins1 {
					pinmux = <STM32_PINMUX('B', 9, AF8)>; /* UART4_TX */
					bias-disable;
					drive-push-pull;
					slew-rate = <0>;
				};
				pins2 {
					pinmux = <STM32_PINMUX('B', 2, AF8)>; /* UART4_RX */
					bias-disable;
				};
			};

			uart4_idle_pins_a: uart4-idle-0 {
				pins1 {
					pinmux = <STM32_PINMUX('G', 11, ANALOG)>; /* UART4_TX */
				};
				pins2 {
					pinmux = <STM32_PINMUX('B', 2, AF8)>; /* UART4_RX */
					bias-disable;
				};
			};

			uart4_sleep_pins_a: uart4-sleep-0 {
				pins {
					pinmux = <STM32_PINMUX('G', 11, ANALOG)>, /* UART4_TX */
						 <STM32_PINMUX('B', 2, ANALOG)>; /* UART4_RX */
				};
			};

			usart3_pins_a: usart3-0 {
				pins1 {
					pinmux = <STM32_PINMUX('B', 10, AF7)>, /* USART3_TX */
						 <STM32_PINMUX('G', 8, AF8)>; /* USART3_RTS */
					bias-disable;
					drive-push-pull;
					slew-rate = <0>;
				};
				pins2 {
					pinmux = <STM32_PINMUX('B', 12, AF8)>, /* USART3_RX */
						 <STM32_PINMUX('B', 13, AF7)>; /* USART3_CTS_NSS */
					bias-disable;
				};
			};

			usart3_idle_pins_a: usart3-idle-0 {
				pins1 {
					pinmux = <STM32_PINMUX('B', 10, ANALOG)>, /* USART3_TX */
						 <STM32_PINMUX('G', 8, ANALOG)>, /* USART3_RTS */
						 <STM32_PINMUX('I', 10, ANALOG)>; /* USART3_CTS_NSS */
				};
				pins2 {
					pinmux = <STM32_PINMUX('B', 12, AF8)>; /* USART3_RX */
					bias-disable;
				};
			};

			usart3_sleep_pins_a: usart3-sleep-0 {
				pins {
					pinmux = <STM32_PINMUX('B', 10, ANALOG)>, /* USART3_TX */
						 <STM32_PINMUX('G', 8, ANALOG)>, /* USART3_RTS */
						 <STM32_PINMUX('I', 10, ANALOG)>, /* USART3_CTS_NSS */
						 <STM32_PINMUX('B', 12, ANALOG)>; /* USART3_RX */
				};
			};

			usart3_pins_b: usart3-1 {
				pins1 {
					pinmux = <STM32_PINMUX('B', 10, AF7)>, /* USART3_TX */
						 <STM32_PINMUX('G', 8, AF8)>; /* USART3_RTS */
					bias-disable;
					drive-push-pull;
					slew-rate = <0>;
				};
				pins2 {
					pinmux = <STM32_PINMUX('B', 12, AF8)>, /* USART3_RX */
						 <STM32_PINMUX('B', 13, AF7)>; /* USART3_CTS_NSS */
					bias-disable;
				};
			};

			usart3_idle_pins_b: usart3-idle-1 {
				pins1 {
					pinmux = <STM32_PINMUX('B', 10, ANALOG)>, /* USART3_TX */
						 <STM32_PINMUX('G', 8, ANALOG)>, /* USART3_RTS */
						 <STM32_PINMUX('B', 13, ANALOG)>; /* USART3_CTS_NSS */
				};
				pins2 {
					pinmux = <STM32_PINMUX('B', 12, AF8)>; /* USART3_RX */
					bias-disable;
				};
			};

			usart3_sleep_pins_b: usart3-sleep-1 {
				pins {
					pinmux = <STM32_PINMUX('B', 10, ANALOG)>, /* USART3_TX */
						 <STM32_PINMUX('G', 8, ANALOG)>, /* USART3_RTS */
						 <STM32_PINMUX('B', 13, ANALOG)>, /* USART3_CTS_NSS */
						 <STM32_PINMUX('B', 12, ANALOG)>; /* USART3_RX */
				};
			};

			usbotg_hs_pins_a: usbotg_hs-0 {
				pins {
					pinmux = <STM32_PINMUX('A', 10, ANALOG)>; /* OTG_ID */
				};
			};
};

&pinctrl_z {

	btreg: bt_reg_on-0 {
		pins {
			pinmux = <STM32_PINMUX('Z', 6, GPIO)>;
			drive-push-pull;
			bias-pull-up;
			output-high;
			slew-rate = <0>;
		};
	};

	usart1_pins_a: usart1-0 {
		pins1 {
			pinmux = <STM32_PINMUX('Z', 7, AF7)>; /* USART1_TX */
			bias-disable;
			drive-push-pull;
			slew-rate = <0>;
		};
		pins2 {
			pinmux = <STM32_PINMUX('Z', 6, AF7)>; /* USART1_RX */
			bias-disable;
		};
	};

	usart1_idle_pins_a: usart1-idle-0 {
		pins1 {
			pinmux = <STM32_PINMUX('Z', 7, ANALOG)>; /* USART1_TX */
		};
		pins2 {
			pinmux = <STM32_PINMUX('Z', 6, AF7)>; /* USART1_RX */
			bias-disable;
		};
	};

	usart1_sleep_pins_a: usart1-sleep-0 {
		pins {
			pinmux = <STM32_PINMUX('Z', 7, ANALOG)>, /* USART1_TX */
				 <STM32_PINMUX('Z', 6, ANALOG)>; /* USART1_RX */
		};
	};

	spi1_pins_a: spi1-0 {
		pins1 {
			pinmux = <STM32_PINMUX('Z', 0, AF5)>, /* SPI1_SCK */
				 <STM32_PINMUX('B', 5, AF5)>; /* SPI1_MOSI */
			bias-disable;
			drive-push-pull;
			slew-rate = <1>;
		};
		pins2 {
			pinmux = <STM32_PINMUX('Z', 1, AF5)>; /* SPI1_MISO */
			bias-disable;
		};
	};

	spi1_sleep_pins_a: spi1-sleep-0 {
		pins {
			pinmux = <STM32_PINMUX('Z', 0, ANALOG)>, /* SPI1_SCK */
				 <STM32_PINMUX('Z', 1, ANALOG)>, /* SPI1_MISO */
				 <STM32_PINMUX('B', 5, ANALOG)>; /* SPI1_MOSI */
		};
	};
};

